# M073 register map
File version: 2.0.2.4
TOSHIBA Cortex-M0 MCU
Registers are 32-bit, read-write, reset 0x0 unless marked. A register's access mark holds for its fields unless they carry their own. Offsets are from the block's base; lines under a group give offsets from that group; [hi:lo] are bit positions; {n}, {i} and the like mark numbered series; 'fields as' and 'values as' point back to an identical list; <NAME> marks a mode.

## Memory map
0x4004C000 DMA blocks up to offset 0x50 — DMA Controller
0x4005F000 DMAIF size 0x4 — DMA Interrupt Flag
0x400C0000 PA blocks up to offset 0x3C — Port A
0x400C0100 PB blocks up to offset 0x3C — Port B
0x400C0300 PD blocks up to offset 0x3C — Port D
0x400C0400 PE blocks up to offset 0x3C — Port E
0x400C0500 PF blocks up to offset 0x3C — Port F
0x400C0600 PG blocks up to offset 0x3C — Port G
0x400C0800 PJ blocks up to offset 0x3C — Port J
0x400C0900 PK blocks up to offset 0x3C — Port K
0x400C0B00 PM blocks up to offset 0x3C — Port M
0x400C0C00 PN blocks up to offset 0x3C — Port N
0x400C4000 TB0 size 0x30 — 16-bit Timer _ Event Counters (TMRB)
{0x400C4000+0x100*n} TB{n} size 0x30 (n=1..9)
0x400E0000 SBI size 0x18 — Serial Bus Interface(SBI)
0x400E1000 SC0 size 0x34 — Serial Channel (SC)
0x400E1100 SC1 size 0x34
0x400E1300 SC3 size 0x34
0x400F1000 OFD size 0x18 — Oscillation Frequency Detector (OFD)
0x400F2000 WD size 0x8 — Watchdog Timer (WD)
0x400F3000 CG blocks up to offset 0x30 — Clock Generator (CG)
0x400F3200 TRMOSC size 0x10 — Internal High-speed Oscillation Adjustment
0x400F3400 NF size 0x8 — Digital Noize FilterClock Control
0x400F4000 VD size 0x4 — Voltage Detection Control Circuit
0x400F5100 INTM0 size 0x8 — Interrupt Mask function
0x400F5200 INTM1 size 0x8 — Interrupt Mask function
0x400F6100 PMD size 0x68 — Programmable Motor Driver (PMD)
0x400F7100 EN size 0x34 — Encoder Input (ENC)
0x400F8000 VE blocks up to offset 0x1BC — Vector Engine (VE)
0x400FD100 AD blocks up to offset 0xD8 — Analog-to-Digital Converter (AD)
0x41FFF000 FC blocks up to offset 0x58 — Flash Control (FC)

## DMA — DMA Controller
Base 0x4004C000
0x00 STATUS ro reset 0x101F0000 — DMA Status Register
  [0] MASTER_ENABLE
0x04 CFG wo reset not defined — DMA Configuration Register
  [0] MASTER_ENABLE
0x08 CTRLBASEPTR — DMA Control Data Base Pointer Register
  [31:10] CTRL_BASE_PTR
0x0C ALTCTRLBASEPTR ro — DMA Channel Alternate Control Data Base Pointer Register
  [31:0] ALT_CTRL_BASE_PTR
0x14 CHNLSWREQUEST wo reset not defined — DMA Channel Software Request Register
  [31:0] CHNL_SW_REQUEST
0x18 CHNLUSEBURSTSET — DMA Channel Useburst Set Register
  [31:0] CHNL_USEBURST_SET
0x1C CHNLUSEBURSTCLR wo reset not defined — DMA Channel Useburst Clear Register
  [31:0] CHNL_USEBURST_CLR
0x20 CHNLREQMASKSET — DMA Channel Request Mask Set Register
  [31:0] CHNL_REQ_MASK_SET
0x24 CHNLREQMASKCLR wo reset not defined — DMA Channel Request Mask Clear Register
  [31:0] CHNL_REQ_MASK_CLR
0x28 CHNLENABLESET — DMA Channel Enable Set Register
  [31:0] CHNL_ENABLE_SET
0x2C CHNLENABLECLR wo reset not defined — DMA Channel Enable Clear Register
  [31:0] CHNL_ENABLE_CLR
0x30 CHNLPRIALTSET — DMA Channel Primary-Alternate Set Register
  [31:0] CHNL_PRI_ALT_SET
0x34 CHNLPRIALTCLR wo reset not defined — DMA Channel Primary-Alternate Clear Register
  [31:0] CHNL_PRI_ALT_CLR
0x38 CHNLPRIORITYSET — DMA Channel Priority Set Register
  [31:0] CHNL_PRIORITY_SET
0x3C CHNLPRIORITYCLR wo reset not defined — DMA Channel Priority Clear Register
  [31:0] CHNL_PRIORITY_CLR
0x4C ERRCLR — DMA Bus Error Clear Register
  [0] ERR_CLR

## DMAIF — DMA Interrupt Flag
Base 0x4005F000
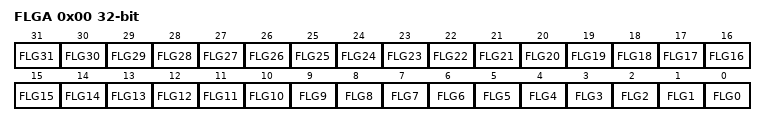
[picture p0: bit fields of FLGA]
0x00 FLGA ro — DMA Flag Register A
  [n] FLG{n} (n=0..31)

## PA — Port A
Base 0x400C0000
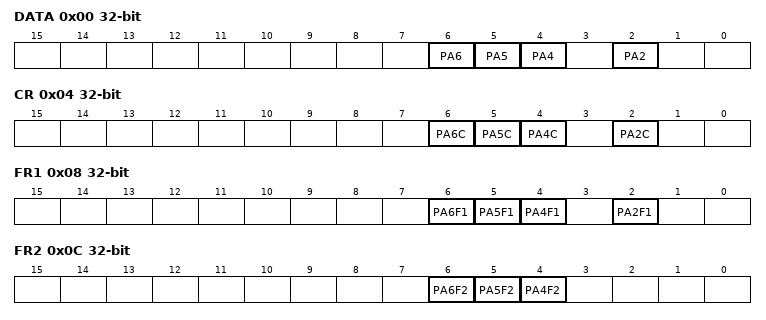
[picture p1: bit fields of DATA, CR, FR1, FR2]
0x00 DATA — Port A Data Register
  [6] PA6, [5] PA5, [4] PA4, [2] PA2
0x04 CR — Port A Output Control Register
  [6] PA6C, [5] PA5C, [4] PA4C, [2] PA2C
0x08 FR1 — Port A Function Register 1
  [6] PA6F1, [5] PA5F1, [4] PA4F1, [2] PA2F1
0x0C FR2 — Port A Function Register 2
  [6] PA6F2, [5] PA5F2, [4] PA4F2
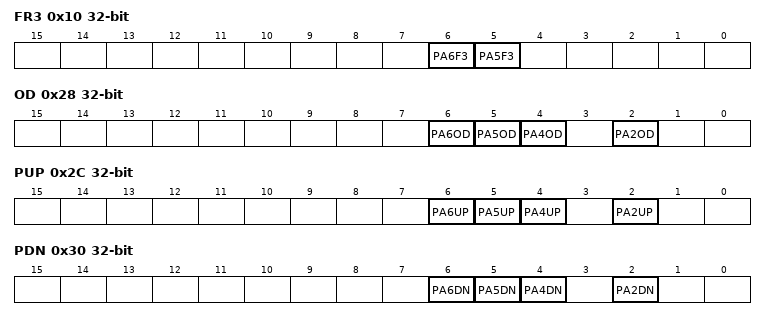
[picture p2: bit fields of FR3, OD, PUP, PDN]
0x10 FR3 — Port A Function Register 3
  [6] PA6F3, [5] PA5F3
0x28 OD — Port A Open Drain Control Register
  [6] PA6OD, [5] PA5OD, [4] PA4OD, [2] PA2OD
0x2C PUP — Port A Pull-up Control Register
  [6] PA6UP, [5] PA5UP, [4] PA4UP, [2] PA2UP
0x30 PDN — Port A Pull-down Control Register
  [6] PA6DN, [5] PA5DN, [4] PA4DN, [2] PA2DN
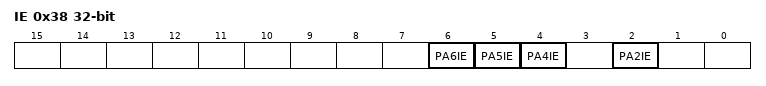
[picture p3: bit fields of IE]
0x38 IE — Port A Input Control Register
  [6] PA6IE, [5] PA5IE, [4] PA4IE, [2] PA2IE
